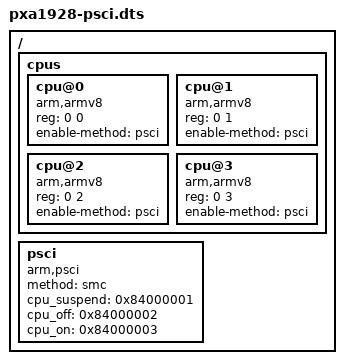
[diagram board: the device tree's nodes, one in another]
/*
 * PXA1928 FPGA Board With PSCI Support
 */

#include "pxa1928concord.dts"

/ {
	cpus {
		#address-cells = <2>;
		#size-cells = <0>;

		cpu@0 {
			device_type = "cpu";
			compatible = "arm,armv8";
			reg = <0 0>;
			enable-method = "psci";
		};
		cpu@1 {
			device_type = "cpu";
			compatible = "arm,armv8";
			reg = <0 1>;
			enable-method = "psci";
		};
		cpu@2 {
			device_type = "cpu";
			compatible = "arm,armv8";
			reg = <0 2>;
			enable-method = "psci";
		};
		cpu@3 {
			device_type = "cpu";
			compatible = "arm,armv8";
			reg = <0 3>;
			enable-method = "psci";
		};
	};

	psci {
		compatible      = "arm,psci";
		method          = "smc";
		cpu_suspend     = <0x84000001>;
		cpu_off		= <0x84000002>;
		cpu_on		= <0x84000003>;
	};
};
